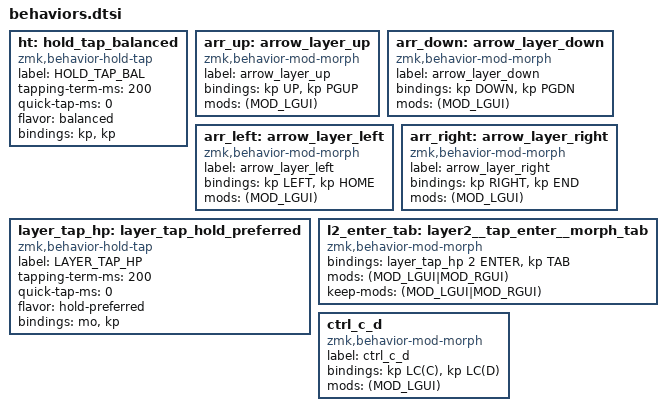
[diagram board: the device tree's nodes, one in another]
// mod-morph: https://zmk.dev/docs/behaviors/mod-morph
//            mods: MOD_LGUI MOD_LSFT MOD_LGUI MOD_LALT
// hold-tap:  https://zmk.dev/docs/behaviors/hold-tap
ht: hold_tap_balanced {
    compatible = "zmk,behavior-hold-tap";
    label = "HOLD_TAP_BAL";
    #binding-cells = <2>;
    tapping-term-ms = <200>;
    quick-tap-ms = <0>;
    flavor = "balanced";
    bindings = <&kp>, <&kp>;
};
arr_up: arrow_layer_up {
    compatible = "zmk,behavior-mod-morph";
    label = "arrow_layer_up";
    #binding-cells = <0>;
    bindings = <&kp UP>, <&kp PGUP>;
    mods = <(MOD_LGUI)>;
};
arr_down: arrow_layer_down {
    compatible = "zmk,behavior-mod-morph";
    label = "arrow_layer_down";
    #binding-cells = <0>;
    bindings = <&kp DOWN>, <&kp PGDN>;
    mods = <(MOD_LGUI)>;
};
arr_left: arrow_layer_left {
    compatible = "zmk,behavior-mod-morph";
    label = "arrow_layer_left";
    #binding-cells = <0>;
    bindings = <&kp LEFT>, <&kp HOME>;
    mods = <(MOD_LGUI)>;
};
arr_right: arrow_layer_right {
    compatible = "zmk,behavior-mod-morph";
    label = "arrow_layer_right";
    #binding-cells = <0>;
    bindings = <&kp RIGHT>, <&kp END>;
    mods = <(MOD_LGUI)>;
};

layer_tap_hp: layer_tap_hold_preferred {
    compatible = "zmk,behavior-hold-tap";
    label = "LAYER_TAP_HP";
    #binding-cells = <2>;
    tapping-term-ms = <200>;
    quick-tap-ms = <0>;
    flavor = "hold-preferred";
    bindings = <&mo>, <&kp>;
};
l2_enter_tab: layer2__tap_enter__morph_tab {
    compatible = "zmk,behavior-mod-morph";
    #binding-cells = <0>;
    bindings = <&layer_tap_hp 2 ENTER>, <&kp TAB>;
    mods = <(MOD_LGUI|MOD_RGUI)>;
    keep-mods = <(MOD_LGUI|MOD_RGUI)>;
};

ctrl_c_d: ctrl_c_d {
    compatible = "zmk,behavior-mod-morph";
    label = "ctrl_c_d";
    #binding-cells = <0>;
    bindings = <&kp LC(C)>, <&kp LC(D)>;
    mods = <(MOD_LGUI)>;
};
